# PY32F002Cxx register map
Vendor: Puya; Series: PY32F0; File version: 1.0.0
CPU: CM0+ r0p1, little endian, no MPU, no FPU, 4 interrupt priority bits
Registers are 32-bit, read-write, reset 0x0 unless marked. A register's access mark holds for its fields unless they carry their own. Offsets are from the block's base; [hi:lo] are bit positions; {n}, {i} and the like mark numbered series.

## COMP2 — Comparator2
Base 0x40010210
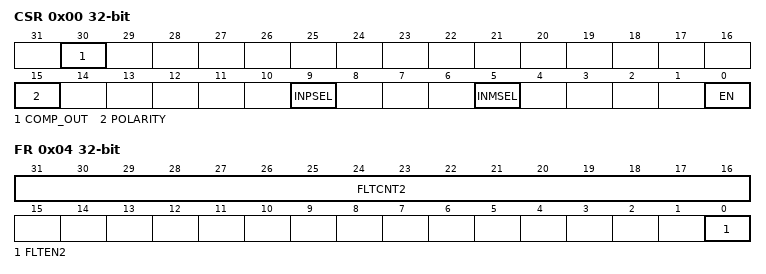
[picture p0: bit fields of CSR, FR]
0x00 CSR — COMP control and status register
  [30] COMP_OUT — Comparator output status
  [15] POLARITY — Comparator polarity selector
  [9] INPSEL — Comparator signal selector for non-inverting input
  [5] INMSEL — Comparator signal selector for inverting input INM
  [0] EN — COMP enable bit
0x04 FR — Comparator Filter register
  [31:16] FLTCNT2 — Comparator filter and counter
  [0] FLTEN2 — Filter enable bit

## CRC — CRC calculation unit
Base 0x40023000
0x00 DR — Data register
  [31:0] DR — Data Register
0x04 IDR — Independent Data register
  [7:0] IDR
0x08 CR — Control register
  [0] RESET — Reset bit

## DBGMCU — Debug support
Base 0x40015800
0x00 IDCODE — MCU Device ID Code Register
  [31:0] REV_ID ro
0x04 CR — Debug MCU Configuration Register
  [1] DBG_STOP — Debug Stop Mode
0x08 APB_FZ1 — APB Freeze Register1
  [31] DBG_LPTIM_STOP — Debug LPTIM stopped when Core ishalted
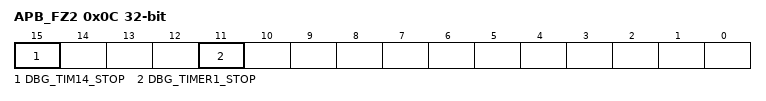
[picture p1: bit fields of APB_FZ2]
0x0C APB_FZ2 — APB Freeze Register2
  [15] DBG_TIM14_STOP — Debug TIM 14 stopped whenCore is halted
  [11] DBG_TIMER1_STOP — Debug Timer 1 stopped when Core ishalted

## EXTI — External interrupt/event controller
Base 0x40021800
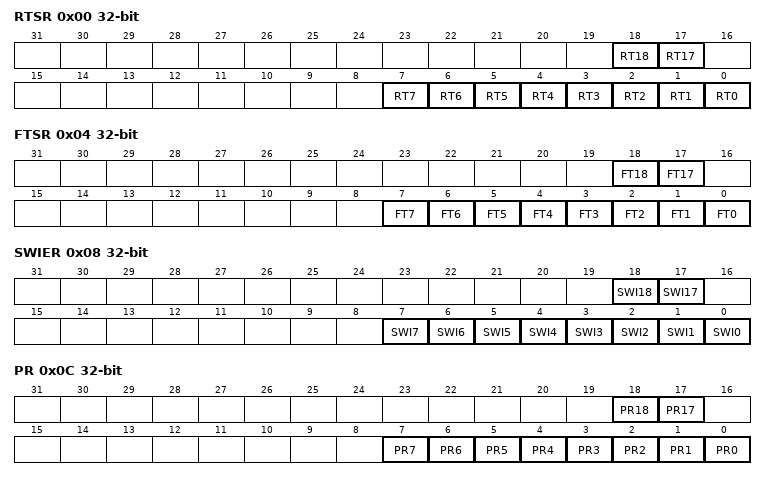
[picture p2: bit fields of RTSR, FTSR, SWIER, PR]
0x00 RTSR — EXTI rising trigger selection register
  [18] RT18 — Rising trigger event configuration bit of Configurable Event input
  [17] RT17 — Rising trigger event configuration bit of Configurable Event input
  [n] RT{n} (n=0..7) — Rising trigger event configuration bit of Configurable Event input
0x04 FTSR — EXTI falling trigger selection register
  [18] FT18 — Falling trigger event configuration bit of Configurable Event input
  [17] FT17 — Falling trigger event configuration bit of Configurable Event input
  [n] FT{n} (n=0..7) — Falling trigger event configuration bit of Configurable Event input
0x08 SWIER — EXTI software interrupt event register
  [18] SWI18 — Rising trigger event configuration bit of Configurable Event input
  [17] SWI17 — Rising trigger event configuration bit of Configurable Event input
  [n] SWI{n} (n=0..7) — Rising trigger event configuration bit of Configurable Event input
0x0C PR — EXTI pending register
  [18] PR18 — configurable event inputs x rising edge Pending bit.
  [17] PR17 — configurable event inputs x rising edge Pending bit.
  [n] PR{n} (n=0..7) — configurable event inputs x rising edge Pending bit.
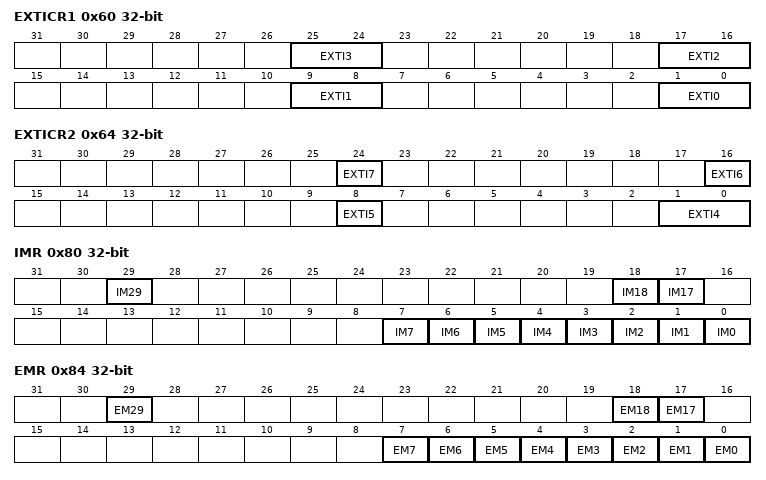
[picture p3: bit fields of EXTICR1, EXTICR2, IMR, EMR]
0x60 EXTICR1 — EXTI external interrupt selection register
  [all] fields
    1=0; 2=1
  [8n+1:8n] EXTI{n} (n=0..3) — GPIO port selection
0x64 EXTICR2 — EXTI external interrupt selection register
  [24] EXTI7 — GPIO port selection
    1=0
  [16] EXTI6 — GPIO port selection
  [8] EXTI5 — GPIO port selection
  [1:0] EXTI4 — GPIO port selection
    1=0; 2=1
0x80 IMR — EXTI CPU wakeup with interrupt mask register
  [29] IM29 — CPU wakeup with interrupt mask on event input
  [18] IM18 — CPU wakeup with interrupt mask on event input
  [17] IM17 — CPU wakeup with interrupt mask on event input
  [n] IM{n} (n=0..7) — CPU wakeup with interrupt mask on event input
0x84 EMR — EXTI CPU wakeup with event mask register
  [29] EM29 — CPU wakeup with event mask on event input
  [18] EM18 — CPU wakeup with event mask on event input
  [17] EM17 — CPU wakeup with event mask on event input
  [n] EM{n} (n=0..7) — CPU wakeup with event mask on event input

## FLASH
Base 0x40022000
0x00 ACR — Access control register
  [0] LATENCY
0x08 KEYR — Flash key register
  [31:0] KEY — Flash key
0x0C OPTKEYR — Option byte key register
  [31:0] OPTKEY — Option byte key
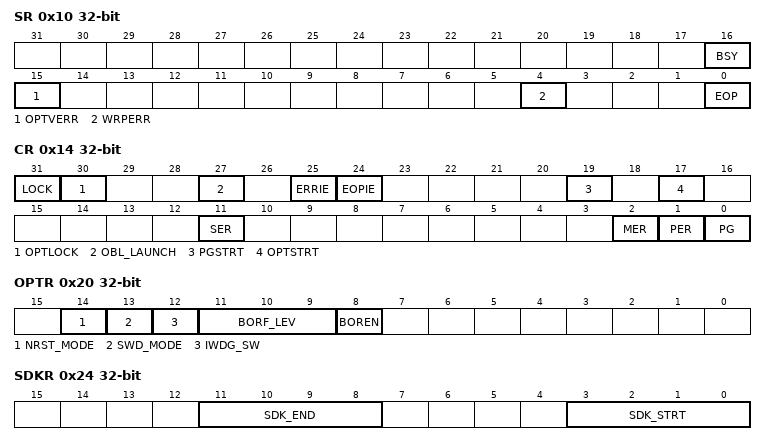
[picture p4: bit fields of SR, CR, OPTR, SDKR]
0x10 SR — Status register
  [16] BSY — Busy
  [15] OPTVERR — Option and Engineering bits loading validity error
  [4] WRPERR — Write protected error
  [0] EOP — End of operation
0x14 CR — Flash control register
  [31] LOCK — FLASH_CR Lock
  [30] OPTLOCK — Options Lock
  [27] OBL_LAUNCH — Force the option byte loading
  [25] ERRIE — Error interrupt enable
  [24] EOPIE — End of operation interrupt enable
  [19] PGSTRT — Flash main memory program start
  [17] OPTSTRT — Option byte program start
  [11] SER — Sector erase
  [2] MER — Mass erase
  [1] PER — Page erase
  [0] PG — Programming
0x20 OPTR — Flash option register
  [14] NRST_MODE
  [13] SWD_MODE
  [12] IWDG_SW — Independent watchdog selection
  [11:9] BORF_LEV — These bits contain the VDD supply level threshold that activates the reset
  [8] BOREN — BOR reset Level
0x24 SDKR — Flash SDK address register
  [11:8] SDK_END — SDK area end address
    1=0; 2=1; 4=2; 8=3
  [3:0] SDK_STRT — SDK area start address
    1=0; 2=1; 4=2; 8=3
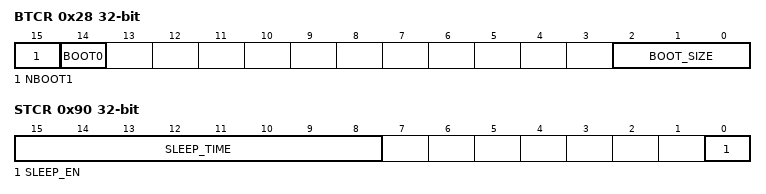
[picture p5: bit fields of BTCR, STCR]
0x28 BTCR — FLASH boot control register
  [15] NBOOT1, [14] BOOT0, [2:0] BOOT_SIZE
0x2C WRPR — Flash WRP address register
  [5:0] WRP — WRP address
0x90 STCR — Flash sleep time config register
  [15:8] SLEEP_TIME — FLash sleep time configuration(counter based on HSI_10M)
  [0] SLEEP_EN — FLash sleep enable
0x100 TS0 — Flash TS0 register
  [8:0] TS0 — FLash TS0 register
0x104 TS1 — Flash TS1 register
  [9:0] TS1 — FLash TS1 register
0x108 TS2P — Flash TS2P register
  [8:0] TS2P — FLash TS2P register
0x10C TPS3 — Flash TPS3 register
  [11:0] TPS3 — FLash TPS3 register
0x110 TS3 — Flash TS3 register
  [8:0] TS3 — FLash TS3 register
0x114 PERTPE — Flash PERTPE register
  [17:0] PERTPE — FLash PERTPE register
0x118 SMERTPE — Flash SMERTPE register
  [17:0] SMERTPE — FLash SMERTPE register
0x11C PRGTPE — Flash PRGTPE register
  [15:0] PRGTPE — FLash PRGTPE register
0x120 PRETPE — Flash PRETPE register
  [13:0] PRETPE — FLash PRETPE register
